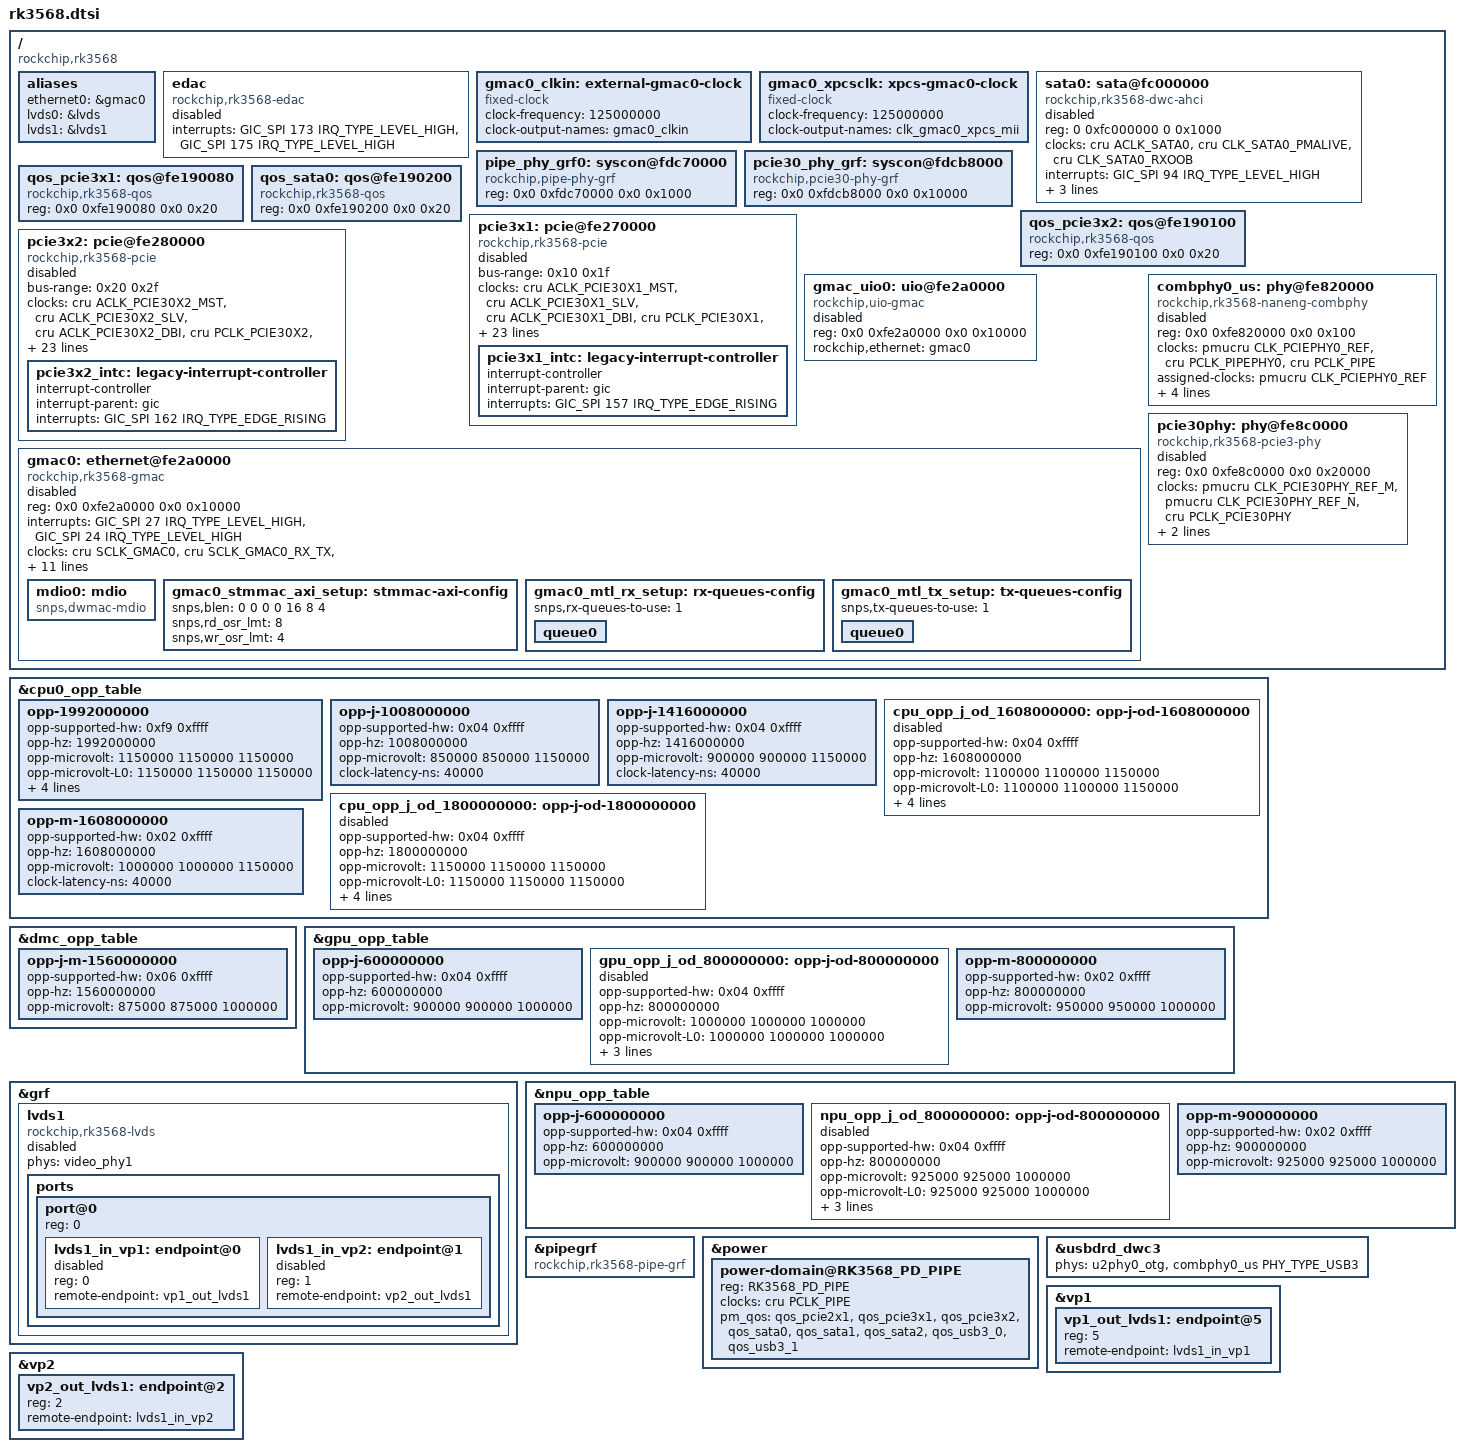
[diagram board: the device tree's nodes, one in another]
// SPDX-License-Identifier: (GPL-2.0+ OR MIT)
/*
 * Copyright (c) 2021 Rockchip Electronics Co., Ltd.
 */

#include "rk356x.dtsi"

/ {
	compatible = "rockchip,rk3568";

	aliases {
		ethernet0 = &gmac0;
		lvds0 = &lvds;
		lvds1 = &lvds1;
	};

	edac: edac {
		compatible = "rockchip,rk3568-edac";
		interrupts = <GIC_SPI 173 IRQ_TYPE_LEVEL_HIGH>,
			     <GIC_SPI 175 IRQ_TYPE_LEVEL_HIGH>;
		interrupt-names = "ce", "ue";
		status = "disabled";
	};

	gmac0_clkin: external-gmac0-clock {
		compatible = "fixed-clock";
		clock-frequency = <125000000>;
		clock-output-names = "gmac0_clkin";
		#clock-cells = <0>;
	};

	gmac0_xpcsclk: xpcs-gmac0-clock {
		compatible = "fixed-clock";
		clock-frequency = <125000000>;
		clock-output-names = "clk_gmac0_xpcs_mii";
		#clock-cells = <0>;
	};

	sata0: sata@fc000000 {
		compatible = "rockchip,rk3568-dwc-ahci", "snps,dwc-ahci";
		reg = <0 0xfc000000 0 0x1000>;
		clocks = <&cru ACLK_SATA0>, <&cru CLK_SATA0_PMALIVE>,
			 <&cru CLK_SATA0_RXOOB>;
		clock-names = "sata", "pmalive", "rxoob";
		interrupts = <GIC_SPI 94 IRQ_TYPE_LEVEL_HIGH>;
		phys = <&combphy0_us PHY_TYPE_SATA>;
		phy-names = "sata-phy";
		ports-implemented = <0x1>;
		power-domains = <&power RK3568_PD_PIPE>;
		status = "disabled";
	};

	pipe_phy_grf0: syscon@fdc70000 {
		compatible = "rockchip,pipe-phy-grf", "syscon";
		reg = <0x0 0xfdc70000 0x0 0x1000>;
	};

	pcie30_phy_grf: syscon@fdcb8000 {
		compatible = "rockchip,pcie30-phy-grf", "syscon";
		reg = <0x0 0xfdcb8000 0x0 0x10000>;
	};

	qos_pcie3x1: qos@fe190080 {
		compatible = "rockchip,rk3568-qos", "syscon";
		reg = <0x0 0xfe190080 0x0 0x20>;
	};

	qos_pcie3x2: qos@fe190100 {
		compatible = "rockchip,rk3568-qos", "syscon";
		reg = <0x0 0xfe190100 0x0 0x20>;
	};

	qos_sata0: qos@fe190200 {
		compatible = "rockchip,rk3568-qos", "syscon";
		reg = <0x0 0xfe190200 0x0 0x20>;
	};

	pcie3x1: pcie@fe270000 {
		compatible = "rockchip,rk3568-pcie", "snps,dw-pcie";
		#address-cells = <3>;
		#size-cells = <2>;
		bus-range = <0x10 0x1f>;
		clocks = <&cru ACLK_PCIE30X1_MST>, <&cru ACLK_PCIE30X1_SLV>,
			 <&cru ACLK_PCIE30X1_DBI>, <&cru PCLK_PCIE30X1>,
			 <&cru CLK_PCIE30X1_AUX_NDFT>;
		clock-names = "aclk_mst", "aclk_slv",
			      "aclk_dbi", "pclk", "aux";
		device_type = "pci";
		interrupts = <GIC_SPI 160 IRQ_TYPE_LEVEL_HIGH>,
			     <GIC_SPI 159 IRQ_TYPE_LEVEL_HIGH>,
			     <GIC_SPI 158 IRQ_TYPE_LEVEL_HIGH>,
			     <GIC_SPI 157 IRQ_TYPE_LEVEL_HIGH>,
			     <GIC_SPI 156 IRQ_TYPE_LEVEL_HIGH>;
		interrupt-names = "sys", "pmc", "msg", "legacy", "err";
		#interrupt-cells = <1>;
		interrupt-map-mask = <0 0 0 7>;
		interrupt-map = <0 0 0 1 &pcie3x1_intc 0>,
				<0 0 0 2 &pcie3x1_intc 1>,
				<0 0 0 3 &pcie3x1_intc 2>,
				<0 0 0 4 &pcie3x1_intc 3>;
		linux,pci-domain = <1>;
		num-ib-windows = <6>;
		num-ob-windows = <2>;
		num-viewport = <8>;
		max-link-speed = <3>;
		msi-map = <0x1000 &its 0x1000 0x1000>;
		num-lanes = <1>;
		phys = <&pcie30phy>;
		phy-names = "pcie-phy";
		power-domains = <&power RK3568_PD_PIPE>;
		reg = <0x3 0xc0400000 0x0 0x00400000>,
		      <0x0 0xfe270000 0x0 0x00010000>,
		      <0x0 0xf2000000 0x0 0x00100000>;
		reg-names = "pcie-dbi", "pcie-apb", "config";
		ranges = <0x01000000 0x0 0xf2100000 0x0 0xf2100000 0x0 0x00100000>,
			 <0x02000000 0x0 0xf2200000 0x0 0xf2200000 0x0 0x01e00000>,
			 <0x03000000 0x3 0x40000000 0x3 0x40000000 0x0 0x40000000>;
		resets = <&cru SRST_PCIE30X1_POWERUP>;
		reset-names = "pipe";
		/* rockchip,bifurcation; lane1 when using 1+1 */
		status = "disabled";

		pcie3x1_intc: legacy-interrupt-controller {
			interrupt-controller;
			#address-cells = <0>;
			#interrupt-cells = <1>;
			interrupt-parent = <&gic>;
			interrupts = <GIC_SPI 157 IRQ_TYPE_EDGE_RISING>;
		};
	};

	pcie3x2: pcie@fe280000 {
		compatible = "rockchip,rk3568-pcie", "snps,dw-pcie";
		#address-cells = <3>;
		#size-cells = <2>;
		bus-range = <0x20 0x2f>;
		clocks = <&cru ACLK_PCIE30X2_MST>, <&cru ACLK_PCIE30X2_SLV>,
			 <&cru ACLK_PCIE30X2_DBI>, <&cru PCLK_PCIE30X2>,
			 <&cru CLK_PCIE30X2_AUX_NDFT>;
		clock-names = "aclk_mst", "aclk_slv",
			      "aclk_dbi", "pclk", "aux";
		device_type = "pci";
		interrupts = <GIC_SPI 165 IRQ_TYPE_LEVEL_HIGH>,
			     <GIC_SPI 164 IRQ_TYPE_LEVEL_HIGH>,
			     <GIC_SPI 163 IRQ_TYPE_LEVEL_HIGH>,
			     <GIC_SPI 162 IRQ_TYPE_LEVEL_HIGH>,
			     <GIC_SPI 161 IRQ_TYPE_LEVEL_HIGH>;
		interrupt-names = "sys", "pmc", "msg", "legacy", "err";
		#interrupt-cells = <1>;
		interrupt-map-mask = <0 0 0 7>;
		interrupt-map = <0 0 0 1 &pcie3x2_intc 0>,
				<0 0 0 2 &pcie3x2_intc 1>,
				<0 0 0 3 &pcie3x2_intc 2>,
				<0 0 0 4 &pcie3x2_intc 3>;
		linux,pci-domain = <2>;
		num-ib-windows = <6>;
		num-viewport = <8>;
		num-ob-windows = <2>;
		max-link-speed = <3>;
		msi-map = <0x2000 &its 0x2000 0x1000>;
		num-lanes = <2>;
		phys = <&pcie30phy>;
		phy-names = "pcie-phy";
		power-domains = <&power RK3568_PD_PIPE>;
		reg = <0x3 0xc0800000 0x0 0x00400000>,
		      <0x0 0xfe280000 0x0 0x00010000>,
		      <0x0 0xf0000000 0x0 0x00100000>;
		reg-names = "pcie-dbi", "pcie-apb", "config";
		ranges = <0x01000000 0x0 0xf0100000 0x0 0xf0100000 0x0 0x00100000>,
			 <0x02000000 0x0 0xf0200000 0x0 0xf0200000 0x0 0x01e00000>,
			 <0x03000000 0x3 0x80000000 0x3 0x80000000 0x0 0x40000000>;
		resets = <&cru SRST_PCIE30X2_POWERUP>;
		reset-names = "pipe";
		/* rockchip,bifurcation; lane0 when using 1+1 */
		status = "disabled";

		pcie3x2_intc: legacy-interrupt-controller {
			interrupt-controller;
			#address-cells = <0>;
			#interrupt-cells = <1>;
			interrupt-parent = <&gic>;
			interrupts = <GIC_SPI 162 IRQ_TYPE_EDGE_RISING>;
		};
	};

	gmac_uio0: uio@fe2a0000 {
		compatible = "rockchip,uio-gmac";
		reg = <0x0 0xfe2a0000 0x0 0x10000>;
		rockchip,ethernet = <&gmac0>;
		status = "disabled";
	};

	gmac0: ethernet@fe2a0000 {
		compatible = "rockchip,rk3568-gmac", "snps,dwmac-4.20a";
		reg = <0x0 0xfe2a0000 0x0 0x10000>;
		interrupts = <GIC_SPI 27 IRQ_TYPE_LEVEL_HIGH>,
			     <GIC_SPI 24 IRQ_TYPE_LEVEL_HIGH>;
		interrupt-names = "macirq", "eth_wake_irq";
		clocks = <&cru SCLK_GMAC0>, <&cru SCLK_GMAC0_RX_TX>,
			 <&cru SCLK_GMAC0_RX_TX>, <&cru CLK_MAC0_REFOUT>,
			 <&cru ACLK_GMAC0>, <&cru PCLK_GMAC0>,
			 <&cru SCLK_GMAC0_RX_TX>, <&cru CLK_GMAC0_PTP_REF>,
			 <&cru PCLK_XPCS>, <&cru CLK_XPCS_EEE>;
		clock-names = "stmmaceth", "mac_clk_rx",
			      "mac_clk_tx", "clk_mac_refout",
			      "aclk_mac", "pclk_mac",
			      "clk_mac_speed", "ptp_ref",
			      "pclk_xpcs", "clk_xpcs_eee";
		resets = <&cru SRST_A_GMAC0>;
		reset-names = "stmmaceth";
		rockchip,grf = <&grf>;
		snps,axi-config = <&gmac0_stmmac_axi_setup>;
		snps,mixed-burst;
		snps,mtl-rx-config = <&gmac0_mtl_rx_setup>;
		snps,mtl-tx-config = <&gmac0_mtl_tx_setup>;
		snps,tso;
		status = "disabled";

		mdio0: mdio {
			compatible = "snps,dwmac-mdio";
			#address-cells = <0x1>;
			#size-cells = <0x0>;
		};

		gmac0_stmmac_axi_setup: stmmac-axi-config {
			snps,blen = <0 0 0 0 16 8 4>;
			snps,rd_osr_lmt = <8>;
			snps,wr_osr_lmt = <4>;
		};

		gmac0_mtl_rx_setup: rx-queues-config {
			snps,rx-queues-to-use = <1>;
			queue0 {};
		};

		gmac0_mtl_tx_setup: tx-queues-config {
			snps,tx-queues-to-use = <1>;
			queue0 {};
		};
	};

	combphy0_us: phy@fe820000 {
		compatible = "rockchip,rk3568-naneng-combphy";
		reg = <0x0 0xfe820000 0x0 0x100>;
		clocks = <&pmucru CLK_PCIEPHY0_REF>,
			 <&cru PCLK_PIPEPHY0>,
			 <&cru PCLK_PIPE>;
		clock-names = "refclk", "apbclk", "pipe_clk";
		assigned-clocks = <&pmucru CLK_PCIEPHY0_REF>;
		assigned-clock-rates = <100000000>;
		resets = <&cru SRST_P_PIPEPHY0>, <&cru SRST_PIPEPHY0>;
		reset-names = "combphy-apb", "combphy";
		rockchip,pipe-grf = <&pipegrf>;
		rockchip,pipe-phy-grf = <&pipe_phy_grf0>;
		#phy-cells = <1>;
		status = "disabled";
	};

	pcie30phy: phy@fe8c0000 {
		compatible = "rockchip,rk3568-pcie3-phy";
		reg = <0x0 0xfe8c0000 0x0 0x20000>;
		#phy-cells = <0>;
		clocks = <&pmucru CLK_PCIE30PHY_REF_M>, <&pmucru CLK_PCIE30PHY_REF_N>,
			 <&cru PCLK_PCIE30PHY>;
		clock-names = "refclk_m", "refclk_n", "pclk";
		resets = <&cru SRST_PCIE30PHY>;
		reset-names = "phy";
		rockchip,phy-grf = <&pcie30_phy_grf>;
		status = "disabled";
	};
};

&cpu0_opp_table {
	opp-1992000000 {
		opp-supported-hw = <0xf9 0xffff>;
		opp-hz = /bits/ 64 <1992000000>;
		opp-microvolt = <1150000 1150000 1150000>;
		opp-microvolt-L0 = <1150000 1150000 1150000>;
		opp-microvolt-L1 = <1150000 1150000 1150000>;
		opp-microvolt-L2 = <1125000 1125000 1150000>;
		opp-microvolt-L3 = <1100000 1100000 1150000>;
		clock-latency-ns = <40000>;
	};

	/* RK3568J cpu OPPs */
	opp-j-1008000000 {
		opp-supported-hw = <0x04 0xffff>;
		opp-hz = /bits/ 64 <1008000000>;
		opp-microvolt = <850000 850000 1150000>;
		clock-latency-ns = <40000>;
	};

	opp-j-1416000000 {
		opp-supported-hw = <0x04 0xffff>;
		opp-hz = /bits/ 64 <1416000000>;
		opp-microvolt = <900000 900000 1150000>;
		clock-latency-ns = <40000>;
	};

	/*
	 * The Max frequency is 1416MHz in default normal mode.
	 * The Max frequency is 1800MHz in overdrive mode,
	 * but under the overdrive mode for a long time,
	 * the chipset may shorten the lifetime, especially in high
	 * temperature condition. Disable overdrive opps by default
	 * and you can enable them in dts file.
	 */
	cpu_opp_j_od_1608000000: opp-j-od-1608000000 {
		opp-supported-hw = <0x04 0xffff>;
		opp-hz = /bits/ 64 <1608000000>;
		opp-microvolt = <1100000 1100000 1150000>;
		opp-microvolt-L0 = <1100000 1100000 1150000>;
		opp-microvolt-L1 = <1050000 1050000 1150000>;
		opp-microvolt-L2 = <1025000 1025000 1150000>;
		opp-microvolt-L3 = <1000000 1000000 1150000>;
		clock-latency-ns = <40000>;
		status = "disabled";
	};

	cpu_opp_j_od_1800000000: opp-j-od-1800000000 {
		opp-supported-hw = <0x04 0xffff>;
		opp-hz = /bits/ 64 <1800000000>;
		opp-microvolt = <1150000 1150000 1150000>;
		opp-microvolt-L0 = <1150000 1150000 1150000>;
		opp-microvolt-L1 = <1100000 1100000 1150000>;
		opp-microvolt-L2 = <1075000 1075000 1150000>;
		opp-microvolt-L3 = <1050000 1050000 1150000>;
		clock-latency-ns = <40000>;
		status = "disabled";
	};

	/* RK3568M cpu OPPs */
	opp-m-1608000000 {
		opp-supported-hw = <0x02 0xffff>;
		opp-hz = /bits/ 64 <1608000000>;
		opp-microvolt = <1000000 1000000 1150000>;
		clock-latency-ns = <40000>;
	};
};

&dmc_opp_table {
	/* RK3568J/M dmc OPPs */
	opp-j-m-1560000000 {
		opp-supported-hw = <0x06 0xffff>;
		opp-hz = /bits/ 64 <1560000000>;
		opp-microvolt = <875000 875000 1000000>;
	};
};

&gpu_opp_table {
	/* RK3568J gpu OPPs */
	opp-j-600000000 {
		opp-supported-hw = <0x04 0xffff>;
		opp-hz = /bits/ 64 <600000000>;
		opp-microvolt = <900000 900000 1000000>;
	};

	/* The Max frequency is 600MHz in default normal mode.
	 * The Max frequency is 800MHz in overdrive mode,
	 * but under the overdrive mode for a long time,
	 * the chipset may shorten the lifetime, especially in high
	 * temperature condition. Disable overdrive opps by default
	 * and you can enable them in dts file.
	 */
	gpu_opp_j_od_800000000: opp-j-od-800000000 {
		opp-supported-hw = <0x04 0xffff>;
		opp-hz = /bits/ 64 <800000000>;
		opp-microvolt = <1000000 1000000 1000000>;
		opp-microvolt-L0 = <1000000 1000000 1000000>;
		opp-microvolt-L1 = <975000 975000 1000000>;
		opp-microvolt-L2 = <950000 950000 1000000>;
		opp-microvolt-L3 = <925000 925000 1000000>;
		status = "disabled";
	};

	/* RK3568M gpu OPPs */
	opp-m-800000000 {
		opp-supported-hw = <0x02 0xffff>;
		opp-hz = /bits/ 64 <800000000>;
		opp-microvolt = <950000 950000 1000000>;
	};
};

&grf {
	lvds1: lvds1 {
		compatible = "rockchip,rk3568-lvds";
		phys = <&video_phy1>;
		phy-names = "phy";
		status = "disabled";

		ports {
			#address-cells = <1>;
			#size-cells = <0>;

			port@0 {
				reg = <0>;
				#address-cells = <1>;
				#size-cells = <0>;

				lvds1_in_vp1: endpoint@0 {
					reg = <0>;
					remote-endpoint = <&vp1_out_lvds1>;
					status = "disabled";
				};

				lvds1_in_vp2: endpoint@1 {
					reg = <1>;
					remote-endpoint = <&vp2_out_lvds1>;
					status = "disabled";
				};
			};
		};
	};
};

&npu_opp_table {
	/* RK3568J npu OPPs */
	opp-j-600000000 {
		opp-supported-hw = <0x04 0xffff>;
		opp-hz = /bits/ 64 <600000000>;
		opp-microvolt = <900000 900000 1000000>;
	};

	/* The Max frequency is 600MHz in default normal mode.
	 * The Max frequency is 800MHz in overdrive mode,
	 * but under the overdrive mode for a long time,
	 * the chipset may shorten the lifetime, especially in high
	 * temperature condition. Disable overdrive opps by default
	 * and you can enable them in dts file.
	 */
	npu_opp_j_od_800000000: opp-j-od-800000000 {
		opp-supported-hw = <0x04 0xffff>;
		opp-hz = /bits/ 64 <800000000>;
		opp-microvolt = <925000 925000 1000000>;
		opp-microvolt-L0 = <925000 925000 1000000>;
		opp-microvolt-L1 = <900000 900000 1000000>;
		opp-microvolt-L2 = <900000 900000 1000000>;
		opp-microvolt-L3 = <900000 900000 1000000>;
		status = "disabled";
	};

	/* RK3568M npu OPPs */
	opp-m-900000000 {
		opp-supported-hw = <0x02 0xffff>;
		opp-hz = /bits/ 64 <900000000>;
		opp-microvolt = <925000 925000 1000000>;
	};
};

&pipegrf {
	compatible = "rockchip,rk3568-pipe-grf", "syscon";
};

&power {
	power-domain@RK3568_PD_PIPE {
		reg = <RK3568_PD_PIPE>;
		clocks = <&cru PCLK_PIPE>;
		pm_qos = <&qos_pcie2x1>,
			 <&qos_pcie3x1>,
			 <&qos_pcie3x2>,
			 <&qos_sata0>,
			 <&qos_sata1>,
			 <&qos_sata2>,
			 <&qos_usb3_0>,
			 <&qos_usb3_1>;
		#power-domain-cells = <0>;
	};
};

&usbdrd_dwc3 {
	phys = <&u2phy0_otg>, <&combphy0_us PHY_TYPE_USB3>;
	phy-names = "usb2-phy", "usb3-phy";
};

&vp1 {
	vp1_out_lvds1: endpoint@5 {
		reg = <5>;
		remote-endpoint = <&lvds1_in_vp1>;
	};
};

&vp2 {
	vp2_out_lvds1: endpoint@2 {
		reg = <2>;
		remote-endpoint = <&lvds1_in_vp2>;
	};
};
